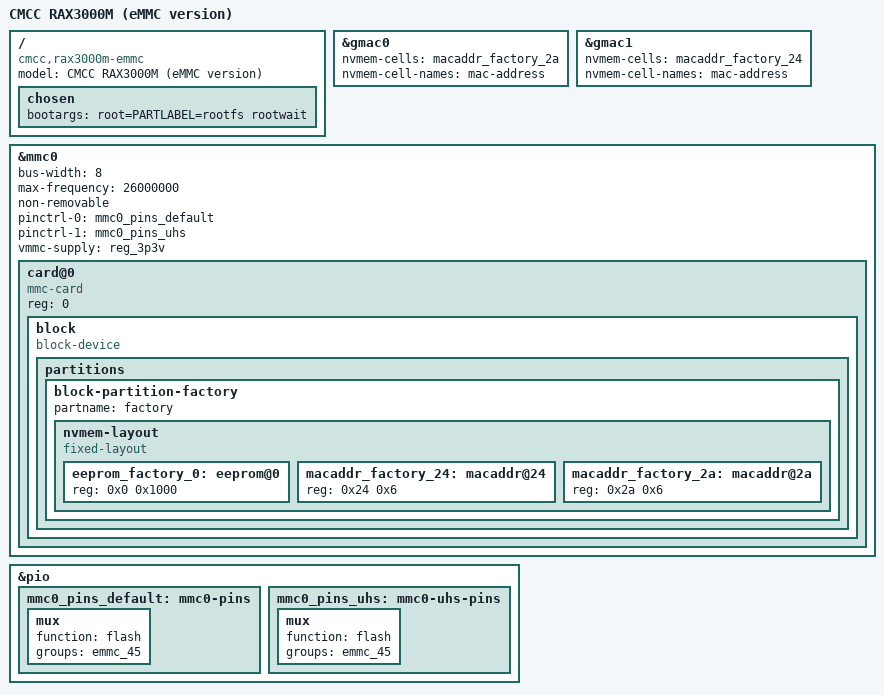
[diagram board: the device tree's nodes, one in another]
// SPDX-License-Identifier: GPL-2.0-or-later OR MIT

/dts-v1/;
#include "mt7981b-cmcc-rax3000m.dts"

/ {
	model = "CMCC RAX3000M (eMMC version)";
	compatible = "cmcc,rax3000m-emmc", "mediatek,mt7981";

	chosen {
		bootargs = "root=PARTLABEL=rootfs rootwait";
	};
};

&gmac0 {
	nvmem-cells = <&macaddr_factory_2a>;
	nvmem-cell-names = "mac-address";
};

&gmac1 {
	nvmem-cells = <&macaddr_factory_24>;
	nvmem-cell-names = "mac-address";
};

&mmc0 {
	bus-width = <8>;
	max-frequency = <26000000>;
	non-removable;
	pinctrl-names = "default", "state_uhs";
	pinctrl-0 = <&mmc0_pins_default>;
	pinctrl-1 = <&mmc0_pins_uhs>;
	vmmc-supply = <&reg_3p3v>;
	#address-cells = <1>;
	#size-cells = <0>;
	status = "okay";

	card@0 {
		compatible = "mmc-card";
		reg = <0>;

		block {
			compatible = "block-device";

			partitions {
				block-partition-factory {
					partname = "factory";

					nvmem-layout {
						compatible = "fixed-layout";
						#address-cells = <1>;
						#size-cells = <1>;

						eeprom_factory_0: eeprom@0 {
							reg = <0x0 0x1000>;
						};

						macaddr_factory_24: macaddr@24 {
							reg = <0x24 0x6>;
						};

						macaddr_factory_2a: macaddr@2a {
							reg = <0x2a 0x6>;
						};
					};
				};
			};
		};
	};
};

&pio {
	mmc0_pins_default: mmc0-pins {
		mux {
			function = "flash";
			groups = "emmc_45";
		};
	};

	mmc0_pins_uhs: mmc0-uhs-pins {
		mux {
			function = "flash";
			groups = "emmc_45";
		};
	};
};
